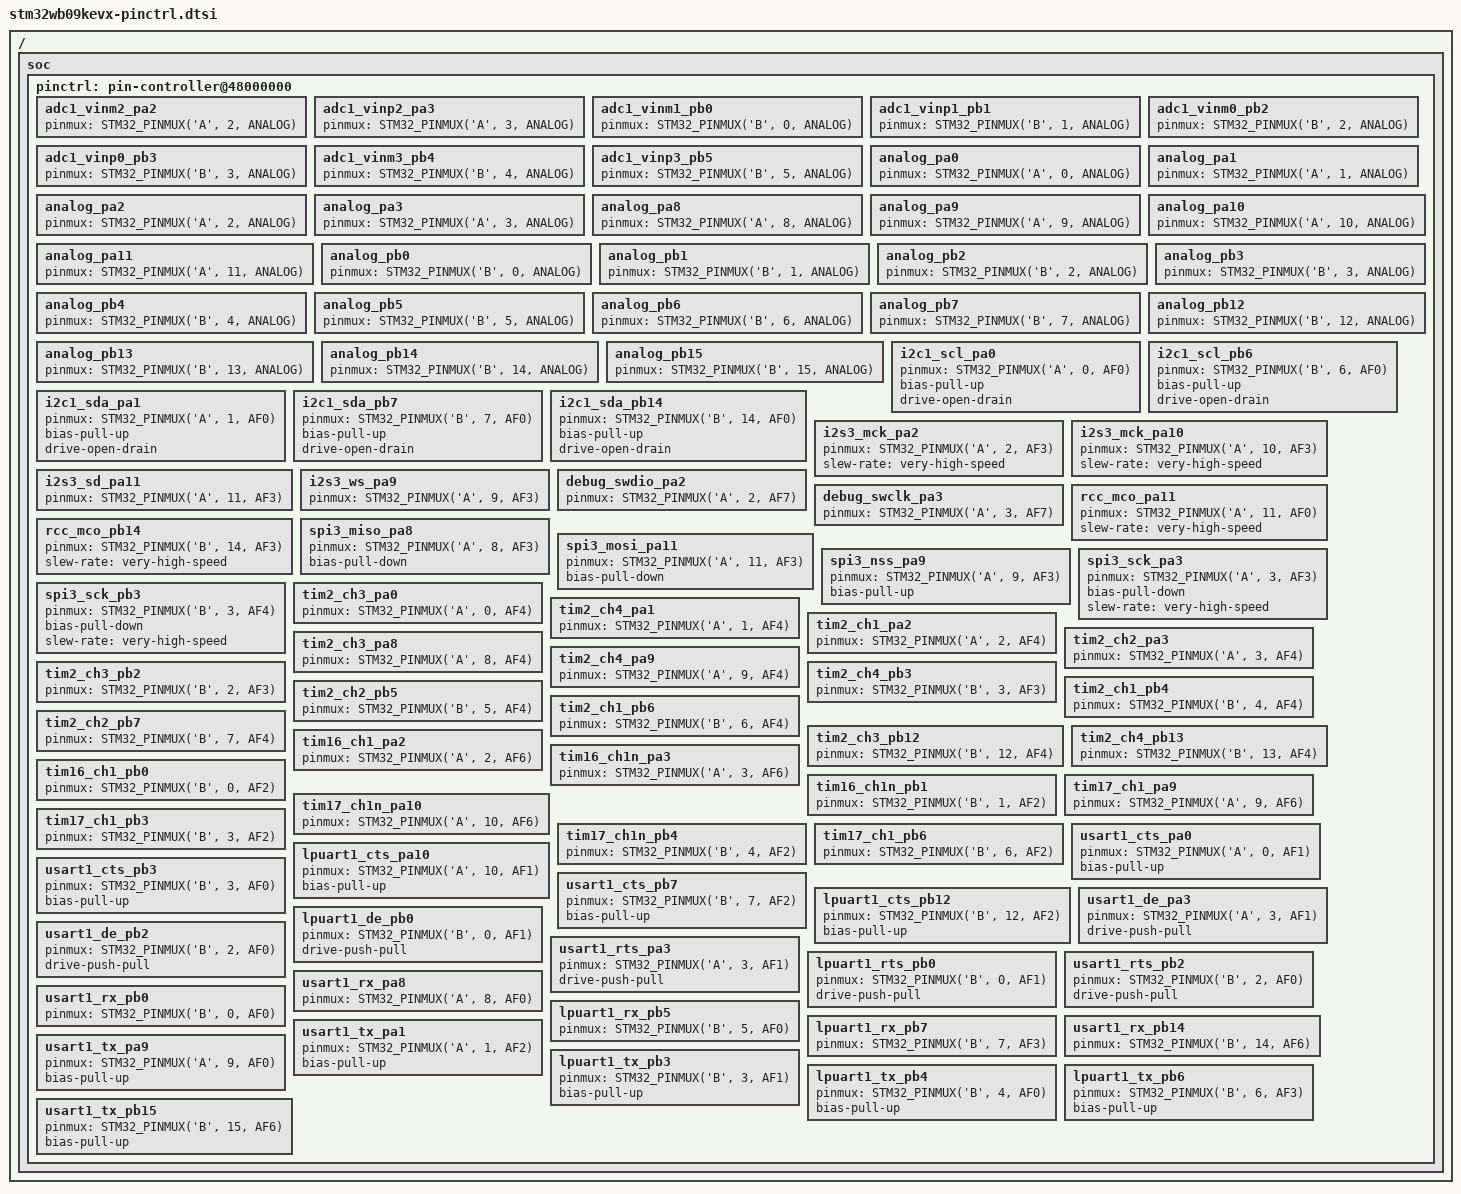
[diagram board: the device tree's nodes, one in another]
/*
 * NOTE: Autogenerated file using genpinctrl.py
 *
 * SPDX-License-Identifier: Apache-2.0
 */

#include <zephyr/dt-bindings/pinctrl/stm32-pinctrl.h>

/ {
	soc {
		pinctrl: pin-controller@48000000 {

			/* ADC_VINM / ADC_VINP */

			/omit-if-no-ref/ adc1_vinm2_pa2: adc1_vinm2_pa2 {
				pinmux = <STM32_PINMUX('A', 2, ANALOG)>;
			};

			/omit-if-no-ref/ adc1_vinp2_pa3: adc1_vinp2_pa3 {
				pinmux = <STM32_PINMUX('A', 3, ANALOG)>;
			};

			/omit-if-no-ref/ adc1_vinm1_pb0: adc1_vinm1_pb0 {
				pinmux = <STM32_PINMUX('B', 0, ANALOG)>;
			};

			/omit-if-no-ref/ adc1_vinp1_pb1: adc1_vinp1_pb1 {
				pinmux = <STM32_PINMUX('B', 1, ANALOG)>;
			};

			/omit-if-no-ref/ adc1_vinm0_pb2: adc1_vinm0_pb2 {
				pinmux = <STM32_PINMUX('B', 2, ANALOG)>;
			};

			/omit-if-no-ref/ adc1_vinp0_pb3: adc1_vinp0_pb3 {
				pinmux = <STM32_PINMUX('B', 3, ANALOG)>;
			};

			/omit-if-no-ref/ adc1_vinm3_pb4: adc1_vinm3_pb4 {
				pinmux = <STM32_PINMUX('B', 4, ANALOG)>;
			};

			/omit-if-no-ref/ adc1_vinp3_pb5: adc1_vinp3_pb5 {
				pinmux = <STM32_PINMUX('B', 5, ANALOG)>;
			};

			/* Analog */

			/omit-if-no-ref/ analog_pa0: analog_pa0 {
				pinmux = <STM32_PINMUX('A', 0, ANALOG)>;
			};

			/omit-if-no-ref/ analog_pa1: analog_pa1 {
				pinmux = <STM32_PINMUX('A', 1, ANALOG)>;
			};

			/omit-if-no-ref/ analog_pa2: analog_pa2 {
				pinmux = <STM32_PINMUX('A', 2, ANALOG)>;
			};

			/omit-if-no-ref/ analog_pa3: analog_pa3 {
				pinmux = <STM32_PINMUX('A', 3, ANALOG)>;
			};

			/omit-if-no-ref/ analog_pa8: analog_pa8 {
				pinmux = <STM32_PINMUX('A', 8, ANALOG)>;
			};

			/omit-if-no-ref/ analog_pa9: analog_pa9 {
				pinmux = <STM32_PINMUX('A', 9, ANALOG)>;
			};

			/omit-if-no-ref/ analog_pa10: analog_pa10 {
				pinmux = <STM32_PINMUX('A', 10, ANALOG)>;
			};

			/omit-if-no-ref/ analog_pa11: analog_pa11 {
				pinmux = <STM32_PINMUX('A', 11, ANALOG)>;
			};

			/omit-if-no-ref/ analog_pb0: analog_pb0 {
				pinmux = <STM32_PINMUX('B', 0, ANALOG)>;
			};

			/omit-if-no-ref/ analog_pb1: analog_pb1 {
				pinmux = <STM32_PINMUX('B', 1, ANALOG)>;
			};

			/omit-if-no-ref/ analog_pb2: analog_pb2 {
				pinmux = <STM32_PINMUX('B', 2, ANALOG)>;
			};

			/omit-if-no-ref/ analog_pb3: analog_pb3 {
				pinmux = <STM32_PINMUX('B', 3, ANALOG)>;
			};

			/omit-if-no-ref/ analog_pb4: analog_pb4 {
				pinmux = <STM32_PINMUX('B', 4, ANALOG)>;
			};

			/omit-if-no-ref/ analog_pb5: analog_pb5 {
				pinmux = <STM32_PINMUX('B', 5, ANALOG)>;
			};

			/omit-if-no-ref/ analog_pb6: analog_pb6 {
				pinmux = <STM32_PINMUX('B', 6, ANALOG)>;
			};

			/omit-if-no-ref/ analog_pb7: analog_pb7 {
				pinmux = <STM32_PINMUX('B', 7, ANALOG)>;
			};

			/omit-if-no-ref/ analog_pb12: analog_pb12 {
				pinmux = <STM32_PINMUX('B', 12, ANALOG)>;
			};

			/omit-if-no-ref/ analog_pb13: analog_pb13 {
				pinmux = <STM32_PINMUX('B', 13, ANALOG)>;
			};

			/omit-if-no-ref/ analog_pb14: analog_pb14 {
				pinmux = <STM32_PINMUX('B', 14, ANALOG)>;
			};

			/omit-if-no-ref/ analog_pb15: analog_pb15 {
				pinmux = <STM32_PINMUX('B', 15, ANALOG)>;
			};

			/* I2C_SCL */

			/omit-if-no-ref/ i2c1_scl_pa0: i2c1_scl_pa0 {
				pinmux = <STM32_PINMUX('A', 0, AF0)>;
				bias-pull-up;
				drive-open-drain;
			};

			/omit-if-no-ref/ i2c1_scl_pb6: i2c1_scl_pb6 {
				pinmux = <STM32_PINMUX('B', 6, AF0)>;
				bias-pull-up;
				drive-open-drain;
			};

			/* I2C_SDA */

			/omit-if-no-ref/ i2c1_sda_pa1: i2c1_sda_pa1 {
				pinmux = <STM32_PINMUX('A', 1, AF0)>;
				bias-pull-up;
				drive-open-drain;
			};

			/omit-if-no-ref/ i2c1_sda_pb7: i2c1_sda_pb7 {
				pinmux = <STM32_PINMUX('B', 7, AF0)>;
				bias-pull-up;
				drive-open-drain;
			};

			/omit-if-no-ref/ i2c1_sda_pb14: i2c1_sda_pb14 {
				pinmux = <STM32_PINMUX('B', 14, AF0)>;
				bias-pull-up;
				drive-open-drain;
			};

			/* I2S_MCK */

			/omit-if-no-ref/ i2s3_mck_pa2: i2s3_mck_pa2 {
				pinmux = <STM32_PINMUX('A', 2, AF3)>;
				slew-rate = "very-high-speed";
			};

			/omit-if-no-ref/ i2s3_mck_pa10: i2s3_mck_pa10 {
				pinmux = <STM32_PINMUX('A', 10, AF3)>;
				slew-rate = "very-high-speed";
			};

			/* I2S_SD */

			/omit-if-no-ref/ i2s3_sd_pa11: i2s3_sd_pa11 {
				pinmux = <STM32_PINMUX('A', 11, AF3)>;
			};

			/* I2S_WS */

			/omit-if-no-ref/ i2s3_ws_pa9: i2s3_ws_pa9 {
				pinmux = <STM32_PINMUX('A', 9, AF3)>;
			};

			/* JTAG PORT */

			/omit-if-no-ref/ debug_swdio_pa2: debug_swdio_pa2 {
				pinmux = <STM32_PINMUX('A', 2, AF7)>;
			};

			/omit-if-no-ref/ debug_swclk_pa3: debug_swclk_pa3 {
				pinmux = <STM32_PINMUX('A', 3, AF7)>;
			};

			/* RCC_MCO */

			/omit-if-no-ref/ rcc_mco_pa11: rcc_mco_pa11 {
				pinmux = <STM32_PINMUX('A', 11, AF0)>;
				slew-rate = "very-high-speed";
			};

			/omit-if-no-ref/ rcc_mco_pb14: rcc_mco_pb14 {
				pinmux = <STM32_PINMUX('B', 14, AF3)>;
				slew-rate = "very-high-speed";
			};

			/* SPI_MISO */

			/omit-if-no-ref/ spi3_miso_pa8: spi3_miso_pa8 {
				pinmux = <STM32_PINMUX('A', 8, AF3)>;
				bias-pull-down;
			};

			/* SPI_MOSI */

			/omit-if-no-ref/ spi3_mosi_pa11: spi3_mosi_pa11 {
				pinmux = <STM32_PINMUX('A', 11, AF3)>;
				bias-pull-down;
			};

			/* SPI_NSS */

			/omit-if-no-ref/ spi3_nss_pa9: spi3_nss_pa9 {
				pinmux = <STM32_PINMUX('A', 9, AF3)>;
				bias-pull-up;
			};

			/* SPI_SCK */

			/omit-if-no-ref/ spi3_sck_pa3: spi3_sck_pa3 {
				pinmux = <STM32_PINMUX('A', 3, AF3)>;
				bias-pull-down;
				slew-rate = "very-high-speed";
			};

			/omit-if-no-ref/ spi3_sck_pb3: spi3_sck_pb3 {
				pinmux = <STM32_PINMUX('B', 3, AF4)>;
				bias-pull-down;
				slew-rate = "very-high-speed";
			};

			/* TIM_CH / TIM_CHN */

			/omit-if-no-ref/ tim2_ch3_pa0: tim2_ch3_pa0 {
				pinmux = <STM32_PINMUX('A', 0, AF4)>;
			};

			/omit-if-no-ref/ tim2_ch4_pa1: tim2_ch4_pa1 {
				pinmux = <STM32_PINMUX('A', 1, AF4)>;
			};

			/omit-if-no-ref/ tim2_ch1_pa2: tim2_ch1_pa2 {
				pinmux = <STM32_PINMUX('A', 2, AF4)>;
			};

			/omit-if-no-ref/ tim2_ch2_pa3: tim2_ch2_pa3 {
				pinmux = <STM32_PINMUX('A', 3, AF4)>;
			};

			/omit-if-no-ref/ tim2_ch3_pa8: tim2_ch3_pa8 {
				pinmux = <STM32_PINMUX('A', 8, AF4)>;
			};

			/omit-if-no-ref/ tim2_ch4_pa9: tim2_ch4_pa9 {
				pinmux = <STM32_PINMUX('A', 9, AF4)>;
			};

			/omit-if-no-ref/ tim2_ch3_pb2: tim2_ch3_pb2 {
				pinmux = <STM32_PINMUX('B', 2, AF3)>;
			};

			/omit-if-no-ref/ tim2_ch4_pb3: tim2_ch4_pb3 {
				pinmux = <STM32_PINMUX('B', 3, AF3)>;
			};

			/omit-if-no-ref/ tim2_ch1_pb4: tim2_ch1_pb4 {
				pinmux = <STM32_PINMUX('B', 4, AF4)>;
			};

			/omit-if-no-ref/ tim2_ch2_pb5: tim2_ch2_pb5 {
				pinmux = <STM32_PINMUX('B', 5, AF4)>;
			};

			/omit-if-no-ref/ tim2_ch1_pb6: tim2_ch1_pb6 {
				pinmux = <STM32_PINMUX('B', 6, AF4)>;
			};

			/omit-if-no-ref/ tim2_ch2_pb7: tim2_ch2_pb7 {
				pinmux = <STM32_PINMUX('B', 7, AF4)>;
			};

			/omit-if-no-ref/ tim2_ch3_pb12: tim2_ch3_pb12 {
				pinmux = <STM32_PINMUX('B', 12, AF4)>;
			};

			/omit-if-no-ref/ tim2_ch4_pb13: tim2_ch4_pb13 {
				pinmux = <STM32_PINMUX('B', 13, AF4)>;
			};

			/omit-if-no-ref/ tim16_ch1_pa2: tim16_ch1_pa2 {
				pinmux = <STM32_PINMUX('A', 2, AF6)>;
			};

			/omit-if-no-ref/ tim16_ch1n_pa3: tim16_ch1n_pa3 {
				pinmux = <STM32_PINMUX('A', 3, AF6)>;
			};

			/omit-if-no-ref/ tim16_ch1_pb0: tim16_ch1_pb0 {
				pinmux = <STM32_PINMUX('B', 0, AF2)>;
			};

			/omit-if-no-ref/ tim16_ch1n_pb1: tim16_ch1n_pb1 {
				pinmux = <STM32_PINMUX('B', 1, AF2)>;
			};

			/omit-if-no-ref/ tim17_ch1_pa9: tim17_ch1_pa9 {
				pinmux = <STM32_PINMUX('A', 9, AF6)>;
			};

			/omit-if-no-ref/ tim17_ch1n_pa10: tim17_ch1n_pa10 {
				pinmux = <STM32_PINMUX('A', 10, AF6)>;
			};

			/omit-if-no-ref/ tim17_ch1_pb3: tim17_ch1_pb3 {
				pinmux = <STM32_PINMUX('B', 3, AF2)>;
			};

			/omit-if-no-ref/ tim17_ch1n_pb4: tim17_ch1n_pb4 {
				pinmux = <STM32_PINMUX('B', 4, AF2)>;
			};

			/omit-if-no-ref/ tim17_ch1_pb6: tim17_ch1_pb6 {
				pinmux = <STM32_PINMUX('B', 6, AF2)>;
			};

			/* UART_CTS / USART_CTS / LPUART_CTS */

			/omit-if-no-ref/ usart1_cts_pa0: usart1_cts_pa0 {
				pinmux = <STM32_PINMUX('A', 0, AF1)>;
				bias-pull-up;
			};

			/omit-if-no-ref/ lpuart1_cts_pa10: lpuart1_cts_pa10 {
				pinmux = <STM32_PINMUX('A', 10, AF1)>;
				bias-pull-up;
			};

			/omit-if-no-ref/ usart1_cts_pb3: usart1_cts_pb3 {
				pinmux = <STM32_PINMUX('B', 3, AF0)>;
				bias-pull-up;
			};

			/omit-if-no-ref/ usart1_cts_pb7: usart1_cts_pb7 {
				pinmux = <STM32_PINMUX('B', 7, AF2)>;
				bias-pull-up;
			};

			/omit-if-no-ref/ lpuart1_cts_pb12: lpuart1_cts_pb12 {
				pinmux = <STM32_PINMUX('B', 12, AF2)>;
				bias-pull-up;
			};

			/* UART_DE / USART_DE / LPUART_DE */

			/omit-if-no-ref/ usart1_de_pa3: usart1_de_pa3 {
				pinmux = <STM32_PINMUX('A', 3, AF1)>;
				drive-push-pull;
			};

			/omit-if-no-ref/ lpuart1_de_pb0: lpuart1_de_pb0 {
				pinmux = <STM32_PINMUX('B', 0, AF1)>;
				drive-push-pull;
			};

			/omit-if-no-ref/ usart1_de_pb2: usart1_de_pb2 {
				pinmux = <STM32_PINMUX('B', 2, AF0)>;
				drive-push-pull;
			};

			/* UART_RTS / USART_RTS / LPUART_RTS */

			/omit-if-no-ref/ usart1_rts_pa3: usart1_rts_pa3 {
				pinmux = <STM32_PINMUX('A', 3, AF1)>;
				drive-push-pull;
			};

			/omit-if-no-ref/ lpuart1_rts_pb0: lpuart1_rts_pb0 {
				pinmux = <STM32_PINMUX('B', 0, AF1)>;
				drive-push-pull;
			};

			/omit-if-no-ref/ usart1_rts_pb2: usart1_rts_pb2 {
				pinmux = <STM32_PINMUX('B', 2, AF0)>;
				drive-push-pull;
			};

			/* UART_RX / USART_RX / LPUART_RX */

			/omit-if-no-ref/ usart1_rx_pa8: usart1_rx_pa8 {
				pinmux = <STM32_PINMUX('A', 8, AF0)>;
			};

			/omit-if-no-ref/ usart1_rx_pb0: usart1_rx_pb0 {
				pinmux = <STM32_PINMUX('B', 0, AF0)>;
			};

			/omit-if-no-ref/ lpuart1_rx_pb5: lpuart1_rx_pb5 {
				pinmux = <STM32_PINMUX('B', 5, AF0)>;
			};

			/omit-if-no-ref/ lpuart1_rx_pb7: lpuart1_rx_pb7 {
				pinmux = <STM32_PINMUX('B', 7, AF3)>;
			};

			/omit-if-no-ref/ usart1_rx_pb14: usart1_rx_pb14 {
				pinmux = <STM32_PINMUX('B', 14, AF6)>;
			};

			/* UART_TX / USART_TX / LPUART_TX */

			/omit-if-no-ref/ usart1_tx_pa1: usart1_tx_pa1 {
				pinmux = <STM32_PINMUX('A', 1, AF2)>;
				bias-pull-up;
			};

			/omit-if-no-ref/ usart1_tx_pa9: usart1_tx_pa9 {
				pinmux = <STM32_PINMUX('A', 9, AF0)>;
				bias-pull-up;
			};

			/omit-if-no-ref/ lpuart1_tx_pb3: lpuart1_tx_pb3 {
				pinmux = <STM32_PINMUX('B', 3, AF1)>;
				bias-pull-up;
			};

			/omit-if-no-ref/ lpuart1_tx_pb4: lpuart1_tx_pb4 {
				pinmux = <STM32_PINMUX('B', 4, AF0)>;
				bias-pull-up;
			};

			/omit-if-no-ref/ lpuart1_tx_pb6: lpuart1_tx_pb6 {
				pinmux = <STM32_PINMUX('B', 6, AF3)>;
				bias-pull-up;
			};

			/omit-if-no-ref/ usart1_tx_pb15: usart1_tx_pb15 {
				pinmux = <STM32_PINMUX('B', 15, AF6)>;
				bias-pull-up;
			};

		};
	};
};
